# PIC32MX370F512L register map
Registers are 32-bit, access not given, reset 0x0 unless marked. A register's access mark holds for its fields unless they carry their own. Offsets are from the block's base; [hi:lo] are bit positions; {n}, {i} and the like mark numbered series; 'fields as' and 'values as' point back to an identical list.

## PORTG — PORTG peripheral
Base 0xBF886600
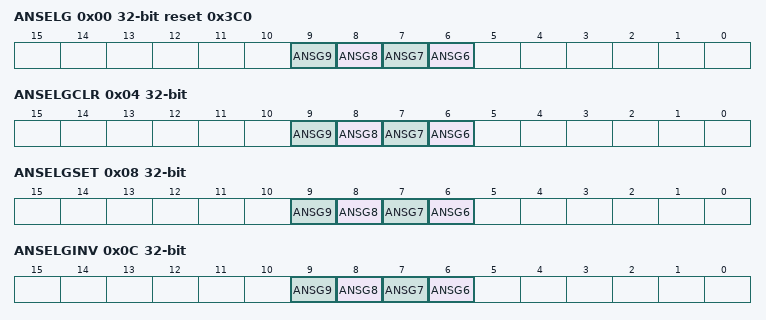
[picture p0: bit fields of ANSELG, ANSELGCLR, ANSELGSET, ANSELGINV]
0x00 ANSELG reset 0x3C0
  [n] ANSG{n} (n=6..9)
0x04 ANSELGCLR
  [n] ANSG{n} (n=6..9)
0x08 ANSELGSET
  [n] ANSG{n} (n=6..9)
0x0C ANSELGINV
  [n] ANSG{n} (n=6..9)
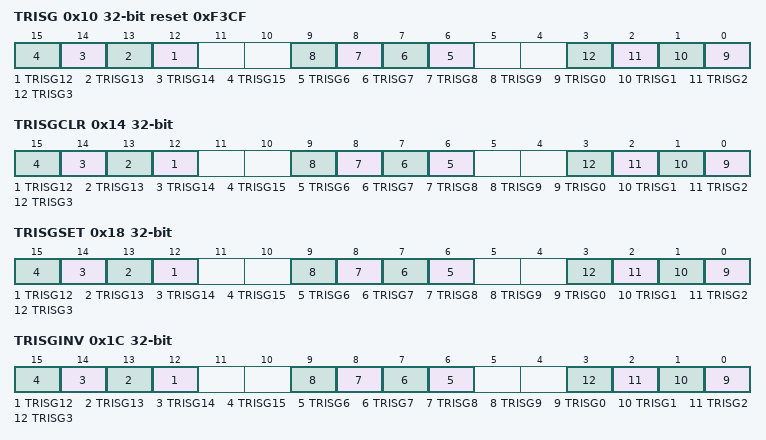
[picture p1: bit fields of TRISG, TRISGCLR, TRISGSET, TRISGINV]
0x10 TRISG reset 0xF3CF
  [n] TRISG{n} (n=12..15), [n] TRISG{n} (n=6..9), [n] TRISG{n} (n=0..3)
0x14 TRISGCLR
  fields as TRISG
0x18 TRISGSET
  fields as TRISG
0x1C TRISGINV
  fields as TRISG
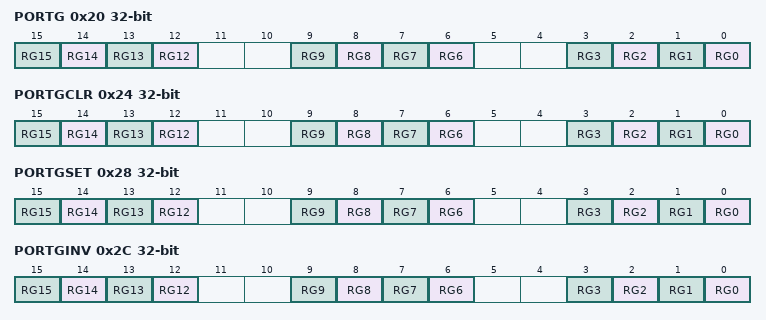
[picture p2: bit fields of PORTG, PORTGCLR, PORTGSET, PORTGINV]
0x20 PORTG
  [n] RG{n} (n=12..15), [n] RG{n} (n=6..9), [n] RG{n} (n=0..3)
0x24 PORTGCLR
  [n] RG{n} (n=12..15), [n] RG{n} (n=6..9), [n] RG{n} (n=0..3)
0x28 PORTGSET
  [n] RG{n} (n=12..15), [n] RG{n} (n=6..9), [n] RG{n} (n=0..3)
0x2C PORTGINV
  [n] RG{n} (n=12..15), [n] RG{n} (n=6..9), [n] RG{n} (n=0..3)
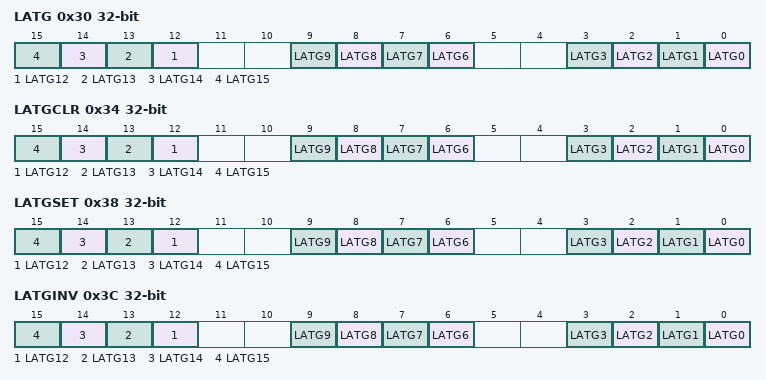
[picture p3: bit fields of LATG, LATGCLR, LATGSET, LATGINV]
0x30 LATG
  [n] LATG{n} (n=12..15), [n] LATG{n} (n=6..9), [n] LATG{n} (n=0..3)
0x34 LATGCLR
  [n] LATG{n} (n=12..15), [n] LATG{n} (n=6..9), [n] LATG{n} (n=0..3)
0x38 LATGSET
  [n] LATG{n} (n=12..15), [n] LATG{n} (n=6..9), [n] LATG{n} (n=0..3)
0x3C LATGINV
  [n] LATG{n} (n=12..15), [n] LATG{n} (n=6..9), [n] LATG{n} (n=0..3)
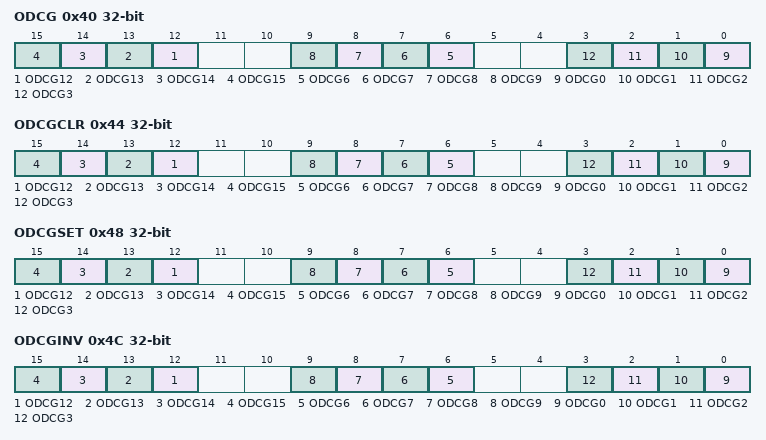
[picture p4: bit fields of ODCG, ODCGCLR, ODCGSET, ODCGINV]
0x40 ODCG
  [n] ODCG{n} (n=12..15), [n] ODCG{n} (n=6..9), [n] ODCG{n} (n=0..3)
0x44 ODCGCLR
  [n] ODCG{n} (n=12..15), [n] ODCG{n} (n=6..9), [n] ODCG{n} (n=0..3)
0x48 ODCGSET
  [n] ODCG{n} (n=12..15), [n] ODCG{n} (n=6..9), [n] ODCG{n} (n=0..3)
0x4C ODCGINV
  [n] ODCG{n} (n=12..15), [n] ODCG{n} (n=6..9), [n] ODCG{n} (n=0..3)
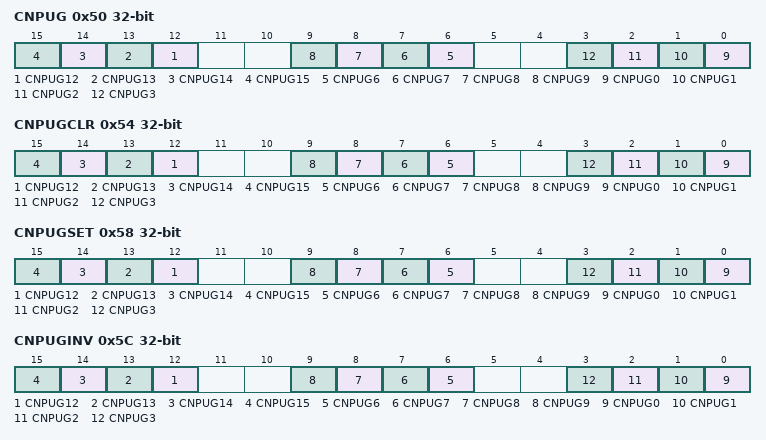
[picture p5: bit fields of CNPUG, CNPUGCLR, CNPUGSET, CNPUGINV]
0x50 CNPUG
  [n] CNPUG{n} (n=12..15), [n] CNPUG{n} (n=6..9), [n] CNPUG{n} (n=0..3)
0x54 CNPUGCLR
  fields as CNPUG
0x58 CNPUGSET
  fields as CNPUG
0x5C CNPUGINV
  fields as CNPUG
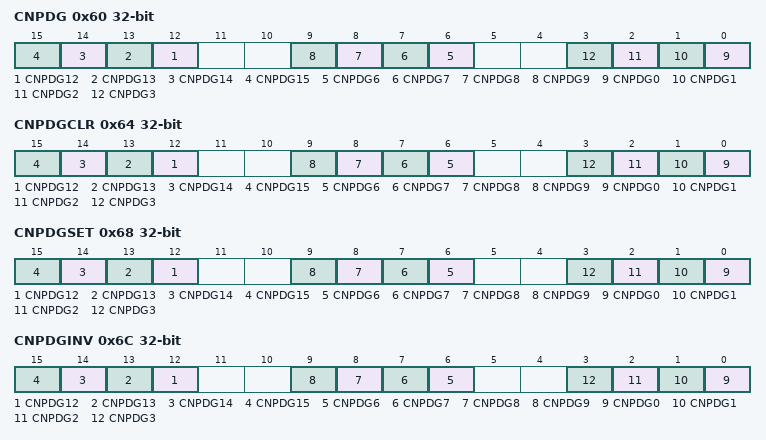
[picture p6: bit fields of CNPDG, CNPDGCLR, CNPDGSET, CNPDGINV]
0x60 CNPDG
  [n] CNPDG{n} (n=12..15), [n] CNPDG{n} (n=6..9), [n] CNPDG{n} (n=0..3)
0x64 CNPDGCLR
  fields as CNPDG
0x68 CNPDGSET
  fields as CNPDG
0x6C CNPDGINV
  fields as CNPDG
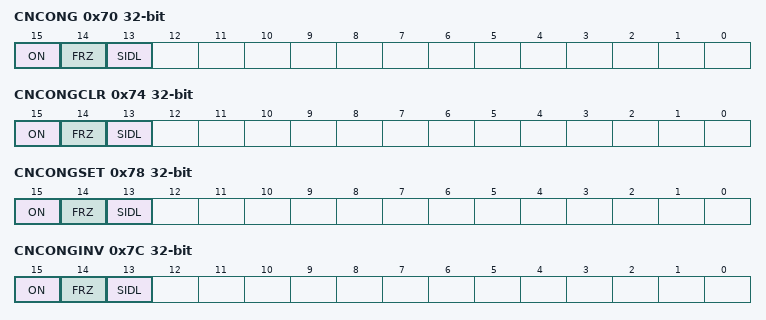
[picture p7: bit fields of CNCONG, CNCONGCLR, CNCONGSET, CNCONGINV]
0x70 CNCONG
  [15] ON, [14] FRZ, [13] SIDL
0x74 CNCONGCLR
  [15] ON, [14] FRZ, [13] SIDL
0x78 CNCONGSET
  [15] ON, [14] FRZ, [13] SIDL
0x7C CNCONGINV
  [15] ON, [14] FRZ, [13] SIDL
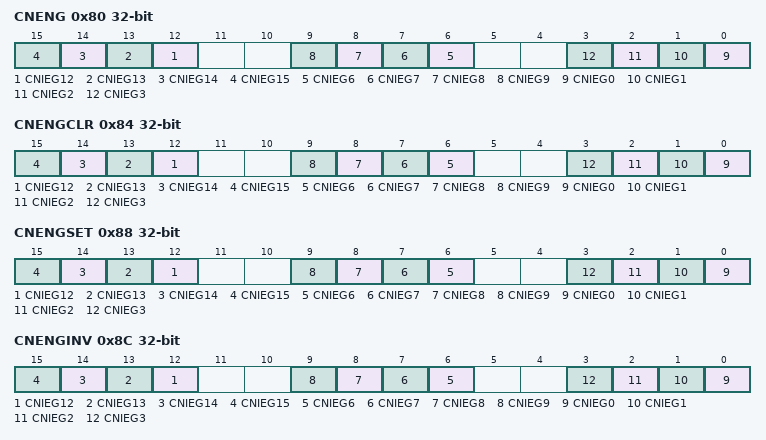
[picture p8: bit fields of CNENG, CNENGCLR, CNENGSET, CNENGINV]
0x80 CNENG
  [n] CNIEG{n} (n=12..15), [n] CNIEG{n} (n=6..9), [n] CNIEG{n} (n=0..3)
0x84 CNENGCLR
  fields as CNENG
0x88 CNENGSET
  fields as CNENG
0x8C CNENGINV
  fields as CNENG
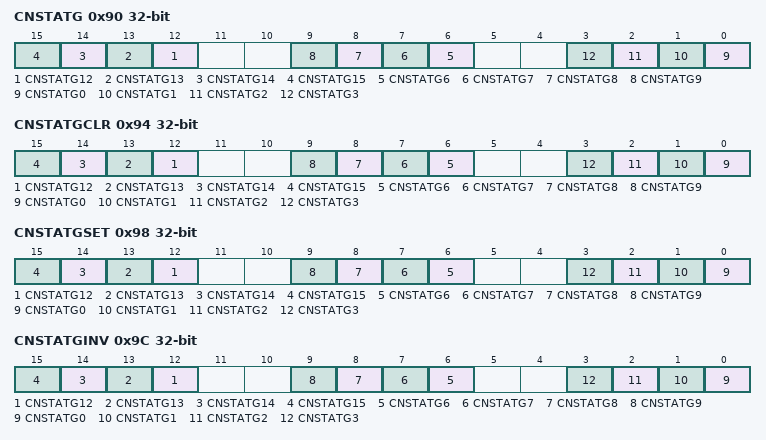
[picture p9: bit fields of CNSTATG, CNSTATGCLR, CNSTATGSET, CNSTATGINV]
0x90 CNSTATG
  [n] CNSTATG{n} (n=12..15), [n] CNSTATG{n} (n=6..9), [n] CNSTATG{n} (n=0..3)
0x94 CNSTATGCLR
  fields as CNSTATG
0x98 CNSTATGSET
  fields as CNSTATG
0x9C CNSTATGINV
  fields as CNSTATG

## OSC — OSC peripheral
Base 0xBF80F000
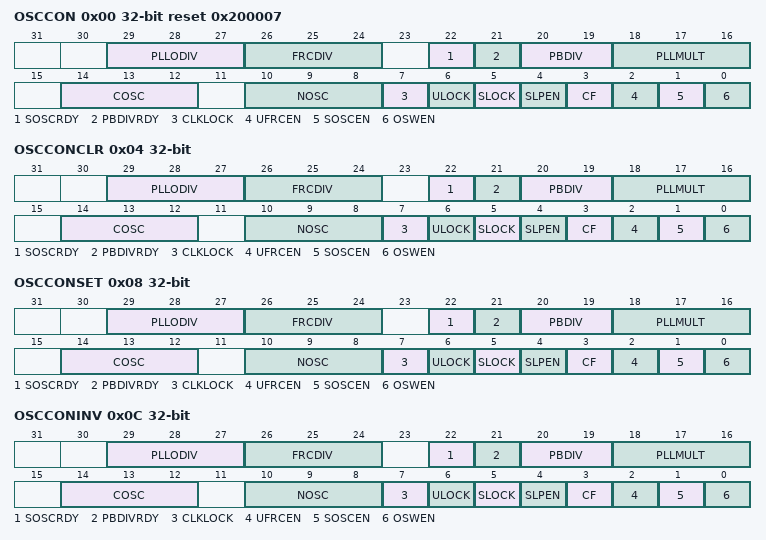
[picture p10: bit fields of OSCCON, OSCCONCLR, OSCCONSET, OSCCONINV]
0x00 OSCCON reset 0x200007
  [29:27] PLLODIV, [26:24] FRCDIV, [22] SOSCRDY, [21] PBDIVRDY, [20:19] PBDIV, [18:16] PLLMULT, [14:12] COSC, [10:8] NOSC, [7] CLKLOCK, [6] ULOCK, [5] SLOCK, [4] SLPEN, [3] CF, [2] UFRCEN, [1] SOSCEN, [0] OSWEN
0x04 OSCCONCLR
  fields as OSCCON
0x08 OSCCONSET
  fields as OSCCON
0x0C OSCCONINV
  fields as OSCCON
0x10 OSCTUN
  [5:0] TUN
0x14 OSCTUNCLR
  [5:0] TUN
0x18 OSCTUNSET
  [5:0] TUN
0x1C OSCTUNINV
  [5:0] TUN
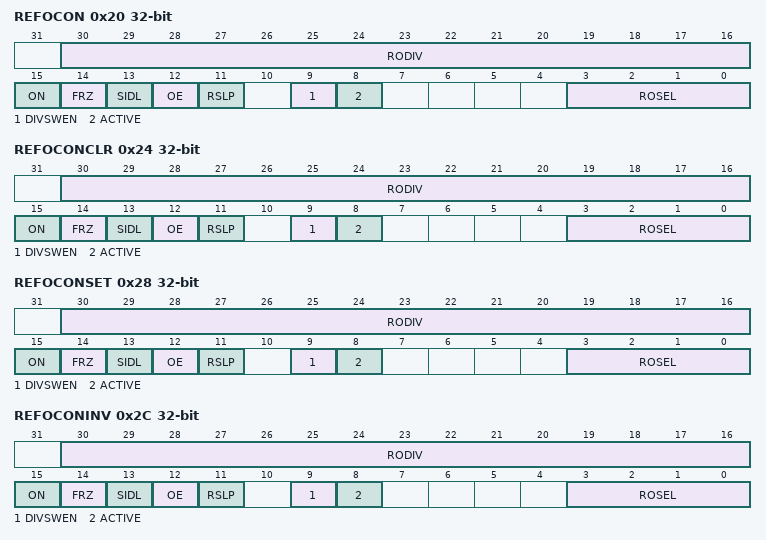
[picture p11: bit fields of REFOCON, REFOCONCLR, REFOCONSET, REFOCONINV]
0x20 REFOCON
  [30:16] RODIV, [15] ON, [14] FRZ, [13] SIDL, [12] OE, [11] RSLP, [9] DIVSWEN, [8] ACTIVE, [3:0] ROSEL
0x24 REFOCONCLR
  fields as REFOCON
0x28 REFOCONSET
  fields as REFOCON
0x2C REFOCONINV
  fields as REFOCON
0x30 REFOTRIM
  [31:23] ROTRIM
0x34 REFOTRIMCLR
  [31:23] ROTRIM
0x38 REFOTRIMSET
  [31:23] ROTRIM
0x3C REFOTRIMINV
  [31:23] ROTRIM

## CFG — CFG peripheral
Base 0xBF80F200
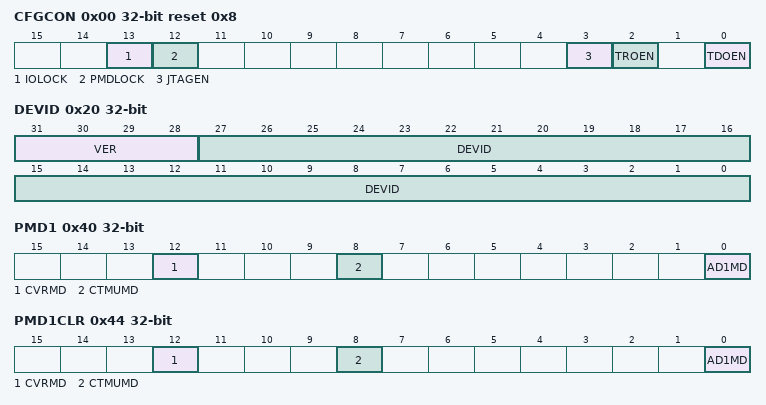
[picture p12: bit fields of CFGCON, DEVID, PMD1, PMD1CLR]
0x00 CFGCON reset 0x8
  [13] IOLOCK, [12] PMDLOCK, [3] JTAGEN, [2] TROEN, [0] TDOEN
0x20 DEVID
  [31:28] VER, [27:0] DEVID
0x30 SYSKEY
0x34 SYSKEYCLR
  [31:0] SYSKEY
0x38 SYSKEYSET
  [31:0] SYSKEY
0x3C SYSKEYINV
  [31:0] SYSKEY
0x40 PMD1
  [12] CVRMD, [8] CTMUMD, [0] AD1MD
0x44 PMD1CLR
  [12] CVRMD, [8] CTMUMD, [0] AD1MD
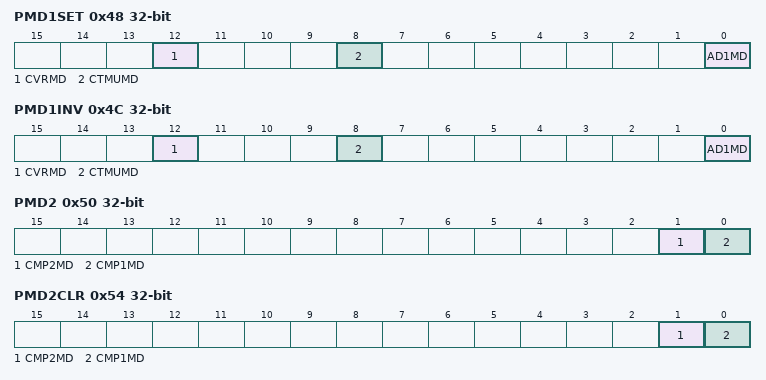
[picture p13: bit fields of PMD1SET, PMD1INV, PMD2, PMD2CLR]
0x48 PMD1SET
  [12] CVRMD, [8] CTMUMD, [0] AD1MD
0x4C PMD1INV
  [12] CVRMD, [8] CTMUMD, [0] AD1MD
0x50 PMD2
  [1] CMP2MD, [0] CMP1MD
0x54 PMD2CLR
  [1] CMP2MD, [0] CMP1MD
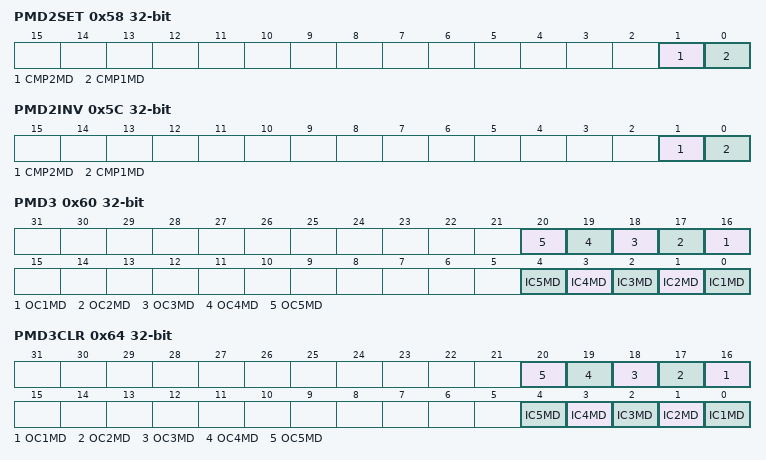
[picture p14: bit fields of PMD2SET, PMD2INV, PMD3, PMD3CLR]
0x58 PMD2SET
  [1] CMP2MD, [0] CMP1MD
0x5C PMD2INV
  [1] CMP2MD, [0] CMP1MD
0x60 PMD3
  [n+15] OC{n}MD (n=1..5), [n-1] IC{n}MD (n=1..5)
0x64 PMD3CLR
  [n+15] OC{n}MD (n=1..5), [n-1] IC{n}MD (n=1..5)
0x68 PMD3SET
  [n+15] OC{n}MD (n=1..5), [n-1] IC{n}MD (n=1..5)
0x6C PMD3INV
  [n+15] OC{n}MD (n=1..5), [n-1] IC{n}MD (n=1..5)
0x70 PMD4
  [n-1] T{n}MD (n=1..5)
0x74 PMD4CLR
  [n-1] T{n}MD (n=1..5)
0x78 PMD4SET
  [n-1] T{n}MD (n=1..5)
0x7C PMD4INV
  [n-1] T{n}MD (n=1..5)
0x80 PMD5
  [17] I2C2MD, [16] I2C1MD, [9] SPI2MD, [8] SPI1MD, [n-1] U{n}MD (n=1..5)
0x84 PMD5CLR
  fields as PMD5
0x88 PMD5SET
  fields as PMD5
0x8C PMD5INV
  fields as PMD5
0x90 PMD6
  [16] PMPMD, [1] REFOMD, [0] RTCCMD
0x94 PMD6CLR
  [16] PMPMD, [1] REFOMD, [0] RTCCMD
0x98 PMD6SET
  [16] PMPMD, [1] REFOMD, [0] RTCCMD
0x9C PMD6INV
  [16] PMPMD, [1] REFOMD, [0] RTCCMD

## NVM — NVM peripheral
Base 0xBF80F400
0x00 NVMCON
  [15] WR, [14] WREN, [13] WRERR, [12] LVDERR, [11] LVDSTAT, [3:0] NVMOP
0x04 NVMCONCLR
  fields as NVMCON
0x08 NVMCONSET
  fields as NVMCON
0x0C NVMCONINV
  fields as NVMCON
0x10 NVMKEY
0x20 NVMADDR
0x24 NVMADDRCLR
  [31:0] NVMADDR
0x28 NVMADDRSET
  [31:0] NVMADDR
0x2C NVMADDRINV
  [31:0] NVMADDR
0x30 NVMDATA
0x40 NVMSRCADDR

## RCON — RCON peripheral
Base 0xBF80F600
0x00 RCON reset 0x3
  [29] HVDR, [9] CMR, [8] VREGS, [7] EXTR, [6] SWR, [4] WDTO, [3] SLEEP, [2] IDLE, [1] BOR, [0] POR
0x04 RCONCLR
  fields as RCON
0x08 RCONSET
  fields as RCON
0x0C RCONINV
  fields as RCON
0x10 RSWRST
  [0] SWRST
0x14 RSWRSTCLR
  [0] SWRST
0x18 RSWRSTSET
  [0] SWRST
0x1C RSWRSTINV
  [0] SWRST

## PPS — PPS peripheral
Base 0xBF80FA04
0x00 INT1R
  [3:0] INT1R
0x04 INT2R
  [3:0] INT2R
0x08 INT3R
  [3:0] INT3R
0x0C INT4R
  [3:0] INT4R
{0xC+4i} T{i}CKR (i=2..5)
  [3:0] T{i}CKR
{0x20+4i} IC{i}R (i=1..5)
  [3:0] IC{i}R
0x44 OCFAR
  [3:0] OCFAR
{0x44+8i} U{i}RXR (i=1..5)
  [3:0] U{i}RXR
{0x48+8i} U{i}CTSR (i=1..5)
  [3:0] U{i}CTSR
0x80 SDI1R
  [3:0] SDI1R
0x84 SS1R
  [3:0] SS1R
0x8C SDI2R
  [3:0] SDI2R
0x90 SS2R
  [3:0] SS2R
0xCC REFCLKIR
  [3:0] REFCLKIR
0x134 RPA14R
  [3:0] RPA14R
0x138 RPA15R
  [3:0] RPA15R
{0x13C+4i} RPB{i}R (i=0..3)
  [3:0] RPB{i}R
{0x13C+4i} RPB{i}R (i=5..10)
  [3:0] RPB{i}R
0x174 RPB14R
  [3:0] RPB14R
0x178 RPB15R
  [3:0] RPB15R
{0x17C+4i} RPC{i}R (i=1..4)
  [3:0] RPC{i}R
0x1B0 RPC13R
  [3:0] RPC13R
0x1B4 RPC14R
  [3:0] RPC14R
{0x1BC+4i} RPD{i}R (i=0..5)
  [3:0] RPD{i}R
{0x1BC+4i} RPD{i}R (i=8..12)
  [3:0] RPD{i}R
0x1F4 RPD14R
  [3:0] RPD14R
0x1F8 RPD15R
  [3:0] RPD15R
0x208 RPE3R
  [3:0] RPE3R
0x210 RPE5R
  [3:0] RPE5R
0x21C RPE8R
  [3:0] RPE8R
0x220 RPE9R
  [3:0] RPE9R
{0x23C+4i} RPF{i}R (i=0..6)
  [3:0] RPF{i}R
0x25C RPF8R
  [3:0] RPF8R
0x26C RPF12R
  [3:0] RPF12R
0x270 RPF13R
  [3:0] RPF13R
0x27C RPG0R
  [3:0] RPG0R
0x280 RPG1R
  [3:0] RPG1R
{0x27C+4i} RPG{i}R (i=6..9)
  [3:0] RPG{i}R
